# CY8C5868AXI_LP035 register map
File version: 0.1
Registers are 8-bit, read-write, no defined reset value unless marked. A register's access mark holds for its fields unless they carry their own. Offsets are from the block's base; [hi:lo] are bit positions; {n}, {i} and the like mark numbered series; 'fields as' and 'values as' point back to an identical list.

## ADC_SAR_1 — SAR ADC
Base 0x00000000
0x40004616 SAR_TR0 — SAR trim register
{0x40005908+i} SAR_CSR{i} (i=0..6) — SAR status and control register {i}
0x40005B28 SAR_SW0 — SAR Analog Routing Register 0
{0x40005B28+i} SAR_SW{i} (i=2..4) — SAR Analog Routing Register {i}
0x40005B2E SAR_SW6 — SAR Analog Routing Register 6
0x40005B2F SAR_CLK — SAR Clock Selection Register
0x40005BA2 SAR_WRK 16-bit — SAR working register

## ADC_SAR_Seq_SAR — SAR ADC
Base 0x00000000
0x40004614 SAR_TR0 — SAR trim register
{0x40005900+i} SAR_CSR{i} (i=0..6) — SAR status and control register {i}
0x40005B20 SAR_SW0 — SAR Analog Routing Register 0
{0x40005B20+i} SAR_SW{i} (i=2..4) — SAR Analog Routing Register {i}
0x40005B26 SAR_SW6 — SAR Analog Routing Register 6
0x40005B27 SAR_CLK — SAR Clock Selection Register
0x40005BA0 SAR_WRK 16-bit — SAR working register

## Opamp_2
Base 0x00000000
0x400043A4 PM_ACT_CFG4 — Active Power Mode Configuration Register 4
  [3:0] EN_OPAMP — Enables subsystems during active power mode
    0=Blk_0 (Enables analog linear output buffer for Opamp block 0); 2=Blk_1 (Enables analog linear output buffer for Opamp block 1); 4=Blk_2 (Enables analog linear output buffer for Opamp block 2); 8=Blk_3 (Enables analog linear output buffer for Opamp block 3)
0x400043B4 PM_STBY_CFG4 — Standby Power Mode Configuration Register 4
  [3:0] EN_OPAMP — Enables subsystems during standby power mode
    values as PM_ACT_CFG4.EN_OPAMP
0x40004624 OPAMP__TR0 — Analog Output Buffer Trim Register 0
  [4:0] offset_trim — Offset Trim: 420uV typical step size; +/- 6.8mV offset trimmable range
0x40004625 OPAMP__TR1 — Analog Output Buffer Trim Register 1
0x4000585C OPAMP__CR — Analog Output Buffer Configuration Register
  [1:0] pwr_mode — Power Mode
    0=Default_Fast (Default Power mode Fast); 1=Slow (Power Mode Slow); 2=Medium (Power Mode Medium); 3=Fast (Power Mode Fast)
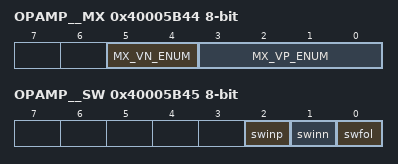
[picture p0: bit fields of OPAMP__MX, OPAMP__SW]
0x40005B44 OPAMP__MX — Analog Buffer Input Selection Register
  [5:4] MX_VN_ENUM — MUX select VN (Negative terminal input)
    0=OPAMP0_MX_VN_DEFAULT (Default - Not Connected (NC)); 1=OPAMP0_MX_VN_AG4 (MUX Selection AGL(4)); 2=OPAMP0_MX_VN_AG6 (MUX Selection AGL(6)); 3=OPAMP0_MX_VN_0x3 (Reserved (NC))
  [3:0] MX_VP_ENUM — MUX select VP (Positive terminal input)
    0=OPAMP0_MX_VP_DEFAULT (Default - Not Connected (NC)); {v}=OPAMP0_MX_VP_AG{v+3} (MUX Selection AGL({v+3})) (v=1..4); {v}=OPAMP0_MX_VP_ABUS{v-5} (MUX Selection ABUSL({v-5})) (v=5..8); 9=OPAMP0_MX_VP_VREF (MUX Selection: OPAMP Voltage Reference); {v}=OPAMP0_MX_VP_H_{0x0+v} (Reserved (NC)) (v=10..15)
0x40005B45 OPAMP__SW — Analog Buffer Routing Switch Register
  [2] swinp — Switch Enable Positive Input
  [1] swinn — Switch Enable Negative Input
  [0] swfol — Switch Enable Follow

## PWM_ADC_CK
Base 0x00000000
0x400043A3 PWM_ADC_CK_GLOBAL_ENABLE — PM.ACT.CFG
  [3:0] en_timer — Enable timer/counters.
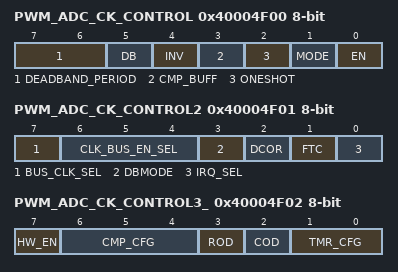
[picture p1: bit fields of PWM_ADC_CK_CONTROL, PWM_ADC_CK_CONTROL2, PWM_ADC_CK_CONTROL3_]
0x40004F00 PWM_ADC_CK_CONTROL — TMRx.CFG0
  [7:6] DEADBAND_PERIOD
  [5] DB — Deadband mode--Deadband phases phi1 and phi2 are outputted on CMP and TC output pins respectively.
    0=Timer (CMP and TC are output.); 1=Deadband (PHI1 (instead of CMP) and PHI2 (instead of TC) are output.)
  [4] INV — Invert sense of TIMEREN signal
  [3] CMP_BUFF — Buffer compare register. Compare register updates only on timer terminal count.
  [2] ONESHOT — Timer stops upon reaching stop condition defined by TMR_CFG bits. Can be restarted by asserting TIMER RESET or disabling and re-enabling block.
  [1] MODE ro — Mode. (0 = Timer; 1 = Comparator)
    0=Timer mode. CNT/CMP register holds timer count value.; 1=Comparator mode. CNT/CMP register holds comparator threshold value.
  [0] EN — Enables timer/comparator.
0x40004F01 PWM_ADC_CK_CONTROL2 — TMRx.CFG1
  [7] BUS_CLK_SEL — Bus Clock selection.
  [6:4] CLK_BUS_EN_SEL — Digital Global Clock selection.
  [3] DBMODE — Deadband mode (asynchronous/synchronous). CMP output pin is also affected when not in deadband mode (CFG0.DEADBAND).
  [2] DCOR — Disable Clear on Read (DCOR) of Status Register SR0.
  [1] FTC — First Terminal Count (FTC). Setting this bit forces a single pulse on the TC pin when first enabled.
    0=Disable_FTC (Disable the single cycle pulse, which signifies the timer is starting.); 1=Enable_FTC (Enable the single cycle pulse, which signifies the timer is starting.)
  [0] IRQ_SEL — Irq selection. (0 = raw interrupts; 1 = status register interrupts)
0x40004F02 PWM_ADC_CK_CONTROL3_ — TMRx.CFG2
  [7] HW_EN — When set Timer Enable controls counting.
  [6:4] CMP_CFG — Comparator configurations
    0=Equal (Compare Equal); 1=Less_than (Compare Less Than); 2=Less_than_or_equal (Compare Less Than or Equal .); 3=Greater (Compare Greater Than .); 4=Greater_than_or_equal (Compare Greater Than or Equal)
  [3] ROD — Reset On Disable (ROD). Resets internal state of output logic
  [2] COD — Clear On Disable (COD). Clears or gates outputs to zero.
  [1:0] TMR_CFG — Timer configuration (MODE = 0): 000 = Continuous; 001 = Pulsewidth; 010 = Period; 011 = Stop on IRQ
    0=Continuous (Timer runs while EN bit of CFG0 register is set to '1'.); 1=Pulsewidth (Timer runs from positive to negative edge of TIMEREN.); 2=Period (Timer runs from positive to positive edge of TIMEREN.); 3=Irq (Timer runs until IRQ.)
0x40004F04 PWM_ADC_CK_PERIOD 16-bit — TMRx.PER0 - Assigned Period
0x40004F06 PWM_ADC_CK_COMPARE 16-bit — TMRx.CNT_CMP0 - Assigned Compare Value
